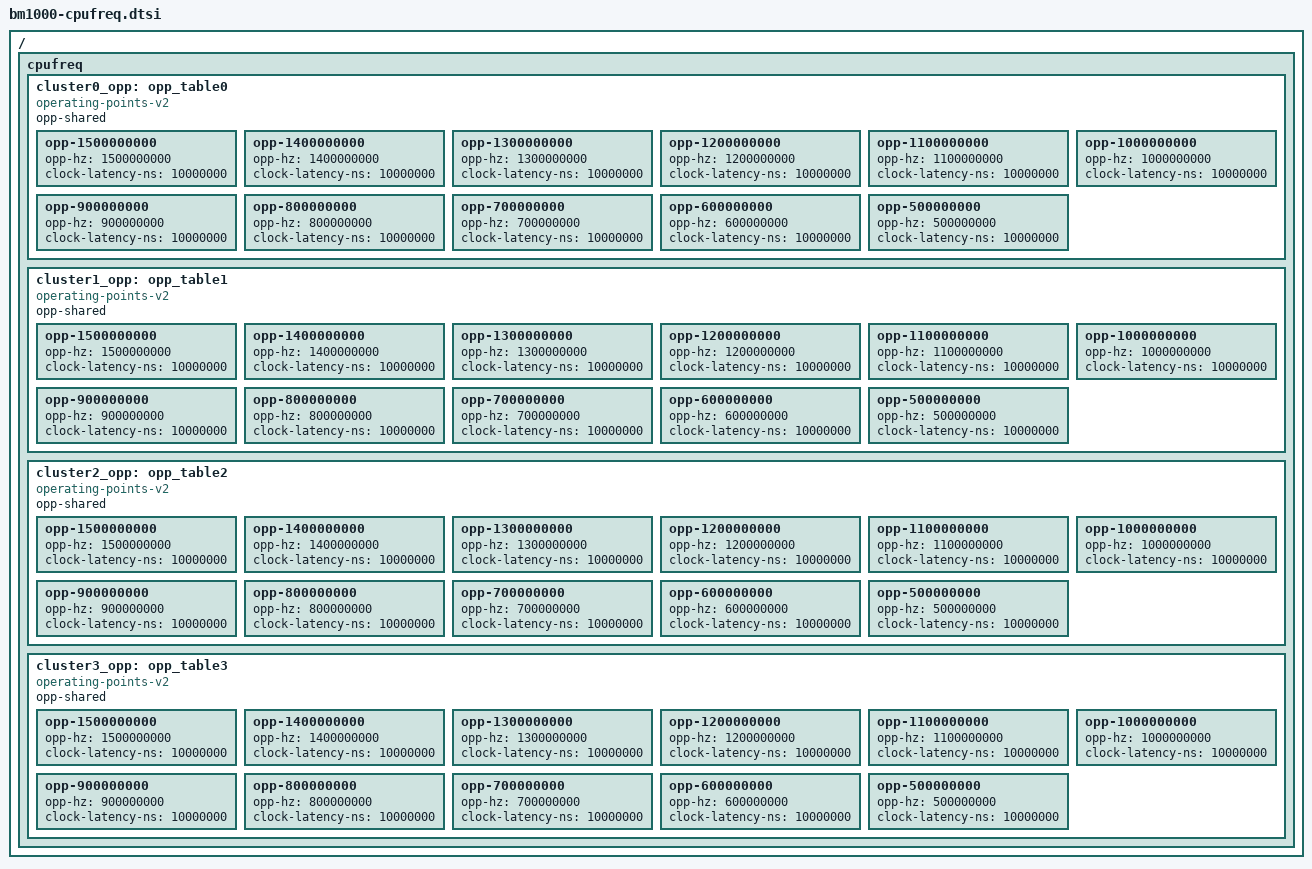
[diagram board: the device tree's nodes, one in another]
// SPDX-License-Identifier: GPL-2.0
/*
 * Device tree include file for BE-M1000 SoC CPU frequencies
 * Copyright (C) 2020-2021 Baikal Electronics, JSC
 */

/ {
	cpufreq {
		cluster0_opp: opp_table0 {
			compatible = "operating-points-v2";
			opp-shared;

			opp-1500000000 {
				opp-hz = /bits/ 64 <1500000000>;
				clock-latency-ns = <10000000>;
			};

			opp-1400000000 {
				opp-hz = /bits/ 64 <1400000000>;
				clock-latency-ns = <10000000>;
			};

			opp-1300000000 {
				opp-hz = /bits/ 64 <1300000000>;
				clock-latency-ns = <10000000>;
			};

			opp-1200000000 {
				opp-hz = /bits/ 64 <1200000000>;
				clock-latency-ns = <10000000>;
			};

			opp-1100000000 {
				opp-hz = /bits/ 64 <1100000000>;
				clock-latency-ns = <10000000>;
			};

			opp-1000000000 {
				opp-hz = /bits/ 64 <1000000000>;
				clock-latency-ns = <10000000>;
			};

			opp-900000000 {
				opp-hz = /bits/ 64 <900000000>;
				clock-latency-ns = <10000000>;
			};

			opp-800000000 {
				opp-hz = /bits/ 64 <800000000>;
				clock-latency-ns = <10000000>;
			};

			opp-700000000 {
				opp-hz = /bits/ 64 <700000000>;
				clock-latency-ns = <10000000>;
			};

			opp-600000000 {
				opp-hz = /bits/ 64 <600000000>;
				clock-latency-ns = <10000000>;
			};

			opp-500000000 {
				opp-hz = /bits/ 64 <500000000>;
				clock-latency-ns = <10000000>;
			};
		};

		cluster1_opp: opp_table1 {
			compatible = "operating-points-v2";
			opp-shared;

			opp-1500000000 {
				opp-hz = /bits/ 64 <1500000000>;
				clock-latency-ns = <10000000>;
			};

			opp-1400000000 {
				opp-hz = /bits/ 64 <1400000000>;
				clock-latency-ns = <10000000>;
			};

			opp-1300000000 {
				opp-hz = /bits/ 64 <1300000000>;
				clock-latency-ns = <10000000>;
			};

			opp-1200000000 {
				opp-hz = /bits/ 64 <1200000000>;
				clock-latency-ns = <10000000>;
			};

			opp-1100000000 {
				opp-hz = /bits/ 64 <1100000000>;
				clock-latency-ns = <10000000>;
			};

			opp-1000000000 {
				opp-hz = /bits/ 64 <1000000000>;
				clock-latency-ns = <10000000>;
			};

			opp-900000000 {
				opp-hz = /bits/ 64 <900000000>;
				clock-latency-ns = <10000000>;
			};

			opp-800000000 {
				opp-hz = /bits/ 64 <800000000>;
				clock-latency-ns = <10000000>;
			};

			opp-700000000 {
				opp-hz = /bits/ 64 <700000000>;
				clock-latency-ns = <10000000>;
			};

			opp-600000000 {
				opp-hz = /bits/ 64 <600000000>;
				clock-latency-ns = <10000000>;
			};

			opp-500000000 {
				opp-hz = /bits/ 64 <500000000>;
				clock-latency-ns = <10000000>;
			};
		};

		cluster2_opp: opp_table2 {
			compatible = "operating-points-v2";
			opp-shared;

			opp-1500000000 {
				opp-hz = /bits/ 64 <1500000000>;
				clock-latency-ns = <10000000>;
			};

			opp-1400000000 {
				opp-hz = /bits/ 64 <1400000000>;
				clock-latency-ns = <10000000>;
			};

			opp-1300000000 {
				opp-hz = /bits/ 64 <1300000000>;
				clock-latency-ns = <10000000>;
			};

			opp-1200000000 {
				opp-hz = /bits/ 64 <1200000000>;
				clock-latency-ns = <10000000>;
			};

			opp-1100000000 {
				opp-hz = /bits/ 64 <1100000000>;
				clock-latency-ns = <10000000>;
			};

			opp-1000000000 {
				opp-hz = /bits/ 64 <1000000000>;
				clock-latency-ns = <10000000>;
			};

			opp-900000000 {
				opp-hz = /bits/ 64 <900000000>;
				clock-latency-ns = <10000000>;
			};

			opp-800000000 {
				opp-hz = /bits/ 64 <800000000>;
				clock-latency-ns = <10000000>;
			};

			opp-700000000 {
				opp-hz = /bits/ 64 <700000000>;
				clock-latency-ns = <10000000>;
			};

			opp-600000000 {
				opp-hz = /bits/ 64 <600000000>;
				clock-latency-ns = <10000000>;
			};

			opp-500000000 {
				opp-hz = /bits/ 64 <500000000>;
				clock-latency-ns = <10000000>;
			};
		};

		cluster3_opp: opp_table3 {
			compatible = "operating-points-v2";
			opp-shared;

			opp-1500000000 {
				opp-hz = /bits/ 64 <1500000000>;
				clock-latency-ns = <10000000>;
			};

			opp-1400000000 {
				opp-hz = /bits/ 64 <1400000000>;
				clock-latency-ns = <10000000>;
			};

			opp-1300000000 {
				opp-hz = /bits/ 64 <1300000000>;
				clock-latency-ns = <10000000>;
			};

			opp-1200000000 {
				opp-hz = /bits/ 64 <1200000000>;
				clock-latency-ns = <10000000>;
			};

			opp-1100000000 {
				opp-hz = /bits/ 64 <1100000000>;
				clock-latency-ns = <10000000>;
			};

			opp-1000000000 {
				opp-hz = /bits/ 64 <1000000000>;
				clock-latency-ns = <10000000>;
			};

			opp-900000000 {
				opp-hz = /bits/ 64 <900000000>;
				clock-latency-ns = <10000000>;
			};

			opp-800000000 {
				opp-hz = /bits/ 64 <800000000>;
				clock-latency-ns = <10000000>;
			};

			opp-700000000 {
				opp-hz = /bits/ 64 <700000000>;
				clock-latency-ns = <10000000>;
			};

			opp-600000000 {
				opp-hz = /bits/ 64 <600000000>;
				clock-latency-ns = <10000000>;
			};

			opp-500000000 {
				opp-hz = /bits/ 64 <500000000>;
				clock-latency-ns = <10000000>;
			};
		};
	};
};
